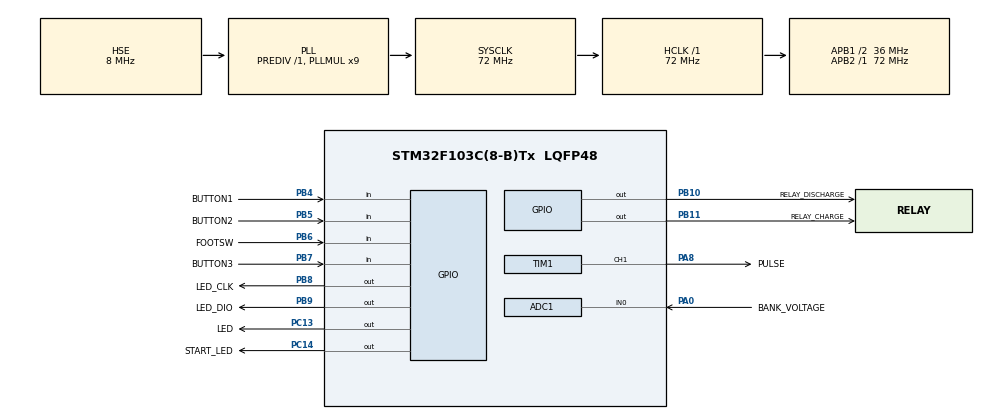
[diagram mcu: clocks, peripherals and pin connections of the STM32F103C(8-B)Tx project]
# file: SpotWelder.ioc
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ADC1.Channel-0\#ChannelRegularConversion=ADC_CHANNEL_0
ADC1.EnableAnalogWatchDog=false
ADC1.NbrOfConversionFlag=1
ADC1.Rank-0\#ChannelRegularConversion=1
ADC1.SamplingTime-0\#ChannelRegularConversion=ADC_SAMPLETIME_55CYCLES_5
ADC1.master=1
Mcu.Family=STM32F1
Mcu.Name=STM32F103C(8-B)Tx
Mcu.Package=LQFP48
NVIC.PriorityGroup=NVIC_PRIORITYGROUP_4
NVIC.TIM1_CC_IRQn=true\:0\:0\:false\:false\:true\:true\:true\:true
PA0-WKUP.GPIO_Label=BANK_VOLTAGE
PA0-WKUP.Signal=ADCx_IN0
PA13.Mode=Trace_Asynchronous_SW
PA13.Signal=SYS_JTMS-SWDIO
PA14.Mode=Trace_Asynchronous_SW
PA14.Signal=SYS_JTCK-SWCLK
PA8.GPIO_Label=PULSE
PA8.GPIO_Speed=GPIO_SPEED_FREQ_HIGH
PA8.Signal=S_TIM1_CH1
PB10.GPIO_Label=RELAY_DISCHARGE
PB10.GPIO_Speed=GPIO_SPEED_FREQ_HIGH
PB10.Signal=GPIO_Output
PB11.GPIO_Label=RELAY_CHARGE
PB11.GPIO_Speed=GPIO_SPEED_FREQ_HIGH
PB11.Signal=GPIO_Output
PB3.Mode=Trace_Asynchronous_SW
PB3.Signal=SYS_JTDO-TRACESWO
PB4.GPIO_Label=BUTTON1
PB4.Signal=GPIO_Input
PB5.GPIO_Label=BUTTON2
PB5.Signal=GPIO_Input
PB6.GPIO_Label=FOOTSW
PB6.Signal=GPIO_Input
PB7.GPIO_Label=BUTTON3
PB7.Signal=GPIO_Input
PB8.GPIO_Label=LED_CLK
PB8.GPIO_ModeDefaultOutputPP=GPIO_MODE_OUTPUT_OD
PB8.GPIO_PuPd=GPIO_NOPULL
PB8.GPIO_Speed=GPIO_SPEED_FREQ_HIGH
PB8.Signal=GPIO_Output
PB9.GPIO_Label=LED_DIO
PB9.GPIO_ModeDefaultOutputPP=GPIO_MODE_OUTPUT_OD
PB9.GPIO_PuPd=GPIO_NOPULL
PB9.GPIO_Speed=GPIO_SPEED_FREQ_HIGH
PB9.Signal=GPIO_Output
PC13-TAMPER-RTC.GPIO_Label=LED
PC13-TAMPER-RTC.GPIO_Speed=GPIO_SPEED_FREQ_HIGH
PC13-TAMPER-RTC.Signal=GPIO_Output
PC14-OSC32_IN.GPIO_Label=START_LED
PC14-OSC32_IN.GPIO_Speed=GPIO_SPEED_FREQ_HIGH
PC14-OSC32_IN.Signal=GPIO_Output
PD0-OSC_IN.Mode=HSE-External-Oscillator
PD0-OSC_IN.Signal=RCC_OSC_IN
PD1-OSC_OUT.Mode=HSE-External-Oscillator
PD1-OSC_OUT.Signal=RCC_OSC_OUT
ProjectManager.HeapSize=0x200
ProjectManager.StackSize=0x400
ProjectManager.TargetToolchain=STM32CubeIDE
RCC.ADCPresc=RCC_ADCPCLK2_DIV6
RCC.AHBFreq_Value=72000000
RCC.APB1CLKDivider=RCC_HCLK_DIV2
RCC.APB1Freq_Value=36000000
RCC.APB1TimFreq_Value=72000000
RCC.APB2Freq_Value=72000000
RCC.APB2TimFreq_Value=72000000
RCC.HCLKFreq_Value=72000000
RCC.PLLMUL=RCC_PLL_MUL9
RCC.PLLSourceVirtual=RCC_PLLSOURCE_HSE
RCC.SYSCLKFreq_VALUE=72000000
RCC.SYSCLKSource=RCC_SYSCLKSOURCE_PLLCLK
RCC.USBFreq_Value=72000000
SH.ADCx_IN0.0=ADC1_IN0,IN0
SH.S_TIM1_CH1.0=TIM1_CH1,PWM Generation1 CH1
TIM1.Channel-PWM\ Generation1\ CH1=TIM_CHANNEL_1
TIM1.OC1Preload_PWM=DISABLE
TIM1.OCFastMode_PWM-PWM\ Generation1\ CH1=TIM_OCFAST_ENABLE
TIM1.OCMode_PWM-PWM\ Generation1\ CH1=TIM_OCMODE_PWM1
TIM1.Prescaler=719
VP_TIM1_VS_OPM.Mode=OPM_bit
board=custom

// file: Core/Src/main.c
/* USER CODE BEGIN Header */
/**
  ******************************************************************************
  * @file           : main.c
  * @brief          : Main program body
  ******************************************************************************
  * @attention
  *
  * Copyright (c) 2022 STMicroelectronics.
  * All rights reserved.
  *
  * This software is licensed under terms that can be found in the LICENSE file
  * in the root directory of this software component.
  * If no LICENSE file comes with this software, it is provided AS-IS.
  *
  ******************************************************************************
  */
/* USER CODE END Header */
#include "main.h"
#include "adc.h"
#include "tim.h"
#include "gpio.h"

/* USER CODE BEGIN Includes */
#include "stm32_tm1637.h"
/* USER CODE END Includes */

/* USER CODE BEGIN PV */

uint32_t PulseTime_ms=DEF_PULSE_LENGTH;
uint32_t watch1,watch2,watch3,watch4;
/* USER CODE END PV */

void SystemClock_Config(void);

int main(void)
{

  /* MCU Configuration--------------------------------------------------------*/

  /* Reset of all peripherals, Initializes the Flash interface and the Systick. */
  HAL_Init();

  /* Configure the system clock */
  SystemClock_Config();

  /* Initialize all configured peripherals */
  MX_GPIO_Init();
  MX_TIM1_Init();
  MX_ADC1_Init();
  /* USER CODE BEGIN 2 */

  //DISABLE CHARGING,ENABLE DISCHARGE
  HAL_GPIO_WritePin(RELAY_CHARGE_GPIO_Port, RELAY_CHARGE_Pin,GPIO_PIN_RESET);
  HAL_GPIO_WritePin(RELAY_DISCHARGE_GPIO_Port, RELAY_DISCHARGE_Pin,GPIO_PIN_SET);

  tm1637SetBrightness(7);
  tm1637DisplayDecimal(3333, 0);

  LL_TIM_OC_SetCompareCH1(TIM1,PulseTime_ms*100);
  LL_TIM_EnableAllOutputs(TIM1); //MOE bit
  LL_TIM_EnableIT_CC1(TIM1);

  /* USER CODE END 2 */

  /* Infinite loop */
  while (1)
  {

    /* USER CODE BEGIN 3 */
	tm1637DisplayDecimal(PulseTime_ms, 0);

	HAL_GPIO_TogglePin(LED_GPIO_Port, LED_Pin);

	HAL_Delay(10);
  }
  /* USER CODE END 3 */
}

void SystemClock_Config(void)
{
  RCC_OscInitTypeDef RCC_OscInitStruct = {0};
  RCC_ClkInitTypeDef RCC_ClkInitStruct = {0};
  RCC_PeriphCLKInitTypeDef PeriphClkInit = {0};

  /** Initializes the RCC Oscillators according to the specified parameters
  * in the RCC_OscInitTypeDef structure.
  */
  RCC_OscInitStruct.OscillatorType = RCC_OSCILLATORTYPE_HSE;
  RCC_OscInitStruct.HSEState = RCC_HSE_ON;
  RCC_OscInitStruct.HSEPredivValue = RCC_HSE_PREDIV_DIV1;
  RCC_OscInitStruct.HSIState = RCC_HSI_ON;
  RCC_OscInitStruct.PLL.PLLState = RCC_PLL_ON;
  RCC_OscInitStruct.PLL.PLLSource = RCC_PLLSOURCE_HSE;
  RCC_OscInitStruct.PLL.PLLMUL = RCC_PLL_MUL9;
  if (HAL_RCC_OscConfig(&RCC_OscInitStruct) != HAL_OK)
  {
    Error_Handler();
  }

  /** Initializes the CPU, AHB and APB buses clocks
  */
  RCC_ClkInitStruct.ClockType = RCC_CLOCKTYPE_HCLK|RCC_CLOCKTYPE_SYSCLK
                              |RCC_CLOCKTYPE_PCLK1|RCC_CLOCKTYPE_PCLK2;
  RCC_ClkInitStruct.SYSCLKSource = RCC_SYSCLKSOURCE_PLLCLK;
  RCC_ClkInitStruct.AHBCLKDivider = RCC_SYSCLK_DIV1;
  RCC_ClkInitStruct.APB1CLKDivider = RCC_HCLK_DIV2;
  RCC_ClkInitStruct.APB2CLKDivider = RCC_HCLK_DIV1;

  if (HAL_RCC_ClockConfig(&RCC_ClkInitStruct, FLASH_LATENCY_2) != HAL_OK)
  {
    Error_Handler();
  }
  PeriphClkInit.PeriphClockSelection = RCC_PERIPHCLK_ADC;
  PeriphClkInit.AdcClockSelection = RCC_ADCPCLK2_DIV6;
  if (HAL_RCCEx_PeriphCLKConfig(&PeriphClkInit) != HAL_OK)
  {
    Error_Handler();
  }
}

void Error_Handler(void)
{
  __disable_irq();
  while (1)
  {
  }
}
